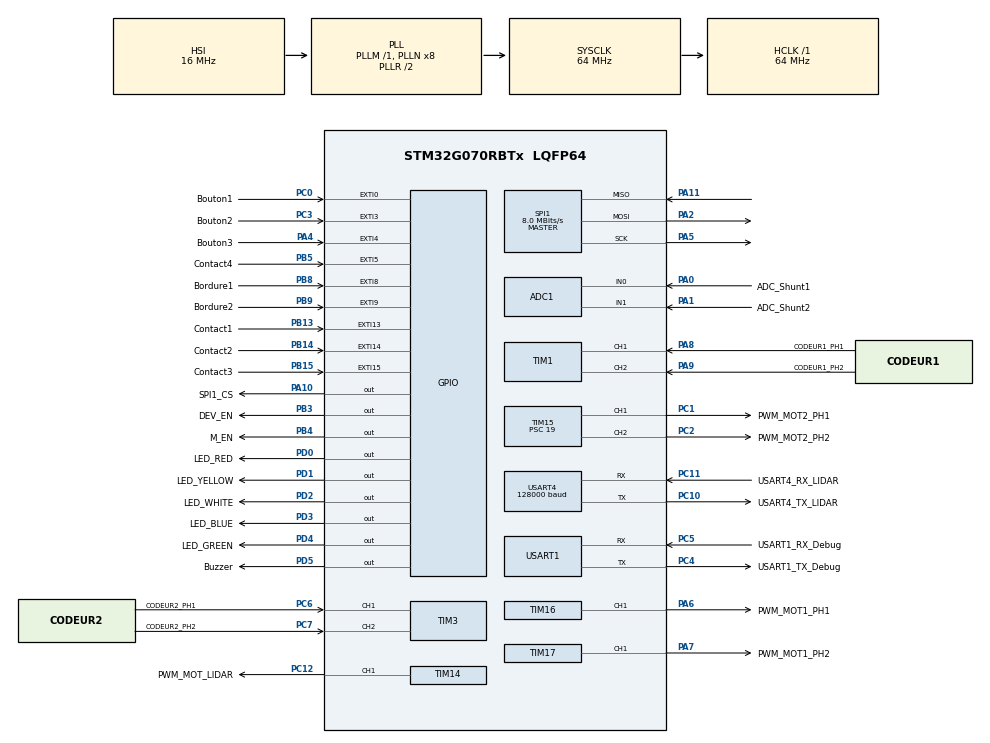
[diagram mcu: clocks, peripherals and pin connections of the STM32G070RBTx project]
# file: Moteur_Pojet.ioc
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ADC1.Channel-2\#ChannelRegularConversion=ADC_CHANNEL_0
ADC1.Channel-3\#ChannelRegularConversion=ADC_CHANNEL_1
ADC1.ContinuousConvMode=ENABLE
ADC1.DMAContinuousRequests=DISABLE
ADC1.ExternalTrigConv=ADC_SOFTWARE_START
ADC1.NbrOfConversion=2
ADC1.NbrOfConversionFlag=1
ADC1.Rank-2\#ChannelRegularConversion=1
ADC1.Rank-3\#ChannelRegularConversion=2
ADC1.SamplingTime-2\#ChannelRegularConversion=ADC_SAMPLINGTIME_COMMON_1
ADC1.SamplingTime-3\#ChannelRegularConversion=ADC_SAMPLINGTIME_COMMON_1
ADC1.SamplingTimeCommon1=ADC_SAMPLETIME_79CYCLES_5
ADC1.SamplingTimeCommon2=ADC_SAMPLETIME_79CYCLES_5
ADC1.SelectedChannel=ADC_CHANNEL_0|ADC_CHANNEL_1
ADC1.Sequencer=FULLY_CONFIGURABLE
ADC1.master=1
Dma.ADC1.0.Direction=DMA_PERIPH_TO_MEMORY
Dma.ADC1.0.EventEnable=DISABLE
Dma.ADC1.0.Instance=DMA1_Channel1
Dma.ADC1.0.MemDataAlignment=DMA_MDATAALIGN_HALFWORD
Dma.ADC1.0.MemInc=DMA_MINC_ENABLE
Dma.ADC1.0.Mode=DMA_NORMAL
Dma.ADC1.0.PeriphDataAlignment=DMA_PDATAALIGN_HALFWORD
Dma.ADC1.0.PeriphInc=DMA_PINC_DISABLE
Dma.ADC1.0.Polarity=HAL_DMAMUX_REQ_GEN_RISING
Dma.ADC1.0.Priority=DMA_PRIORITY_LOW
Dma.ADC1.0.RequestNumber=1
Dma.ADC1.0.SignalID=NONE
Dma.ADC1.0.SyncEnable=DISABLE
Dma.ADC1.0.SyncPolarity=HAL_DMAMUX_SYNC_NO_EVENT
Dma.ADC1.0.SyncRequestNumber=1
Dma.ADC1.0.SyncSignalID=NONE
Dma.Request0=ADC1
Mcu.Family=STM32G0
Mcu.Name=STM32G070RBTx
Mcu.Package=LQFP64
NVIC.DMA1_Channel1_IRQn=true\:0\:0\:false\:false\:true\:false\:true\:true
NVIC.EXTI0_1_IRQn=true\:0\:0\:false\:false\:true\:true\:true\:true
NVIC.EXTI2_3_IRQn=true\:0\:0\:false\:false\:true\:true\:true\:true
NVIC.EXTI4_15_IRQn=true\:0\:0\:false\:false\:true\:true\:true\:true
NVIC.TIM1_CC_IRQn=true\:0\:0\:false\:false\:true\:true\:true\:true
NVIC.TIM3_IRQn=true\:0\:0\:false\:false\:true\:true\:true\:true
PA0.GPIO_Label=ADC_Shunt1
PA0.Mode=IN0
PA0.Signal=ADC1_IN0
PA1.GPIO_Label=ADC_Shunt2
PA1.Mode=IN1
PA1.Signal=ADC1_IN1
PA10.GPIO_Label=SPI1_CS
PA10.PinState=GPIO_PIN_SET
PA10.Signal=GPIO_Output
PA11\ [PA9].Mode=Full_Duplex_Master
PA11\ [PA9].Signal=SPI1_MISO
PA13.Mode=Serial_Wire
PA13.Signal=SYS_SWDIO
PA14-BOOT0.Mode=Serial_Wire
PA14-BOOT0.Signal=SYS_SWCLK
PA2.Mode=Full_Duplex_Master
PA2.Signal=SPI1_MOSI
PA4.GPIO_Label=Bouton3
PA4.GPIO_PuPd=GPIO_NOPULL
PA4.Signal=GPXTI4
PA5.Mode=Full_Duplex_Master
PA5.Signal=SPI1_SCK
PA6.GPIO_Label=PWM_MOT1_PH1
PA6.Signal=S_TIM16_CH1
PA7.GPIO_Label=PWM_MOT1_PH2
PA7.Signal=S_TIM17_CH1
PA8.GPIO_Label=CODEUR1_PH1
PA8.Signal=S_TIM1_CH1
PA9.GPIO_Label=CODEUR1_PH2
PA9.Signal=S_TIM1_CH2
PB13.GPIO_Label=Contact1
PB13.GPIO_PuPd=GPIO_PULLDOWN
PB13.Signal=GPXTI13
PB14.GPIO_Label=Contact2
PB14.GPIO_PuPd=GPIO_PULLDOWN
PB14.Signal=GPXTI14
PB15.GPIO_Label=Contact3
PB15.GPIO_PuPd=GPIO_PULLDOWN
PB15.Signal=GPXTI15
PB3.GPIO_Label=DEV_EN
PB3.Signal=GPIO_Output
PB4.GPIO_Label=M_EN
PB4.Signal=GPIO_Output
PB5.GPIO_Label=Contact4
PB5.GPIO_PuPd=GPIO_PULLDOWN
PB5.Signal=GPXTI5
PB8.GPIO_Label=Bordure1
PB8.Signal=GPXTI8
PB9.GPIO_Label=Bordure2
PB9.Signal=GPXTI9
PC0.GPIO_Label=Bouton1
PC0.Signal=GPXTI0
PC1.GPIO_Label=PWM_MOT2_PH1
PC1.Signal=S_TIM15_CH1
PC10.GPIO_Label=USART4_TX_LIDAR
PC10.Mode=Asynchronous
PC10.Signal=USART4_TX
PC11.GPIO_Label=USART4_RX_LIDAR
PC11.Mode=Asynchronous
PC11.Signal=USART4_RX
PC12.GPIO_Label=PWM_MOT_LIDAR
PC12.Signal=S_TIM14_CH1
PC2.GPIO_Label=PWM_MOT2_PH2
PC2.Signal=S_TIM15_CH2
PC3.GPIO_Label=Bouton2
PC3.Signal=GPXTI3
PC4.GPIO_Label=USART1_TX_Debug
PC4.Mode=Asynchronous
PC4.Signal=USART1_TX
PC5.GPIO_Label=USART1_RX_Debug
PC5.Mode=Asynchronous
PC5.Signal=USART1_RX
PC6.GPIO_Label=CODEUR2_PH1
PC6.Signal=S_TIM3_CH1
PC7.GPIO_Label=CODEUR2_PH2
PC7.Signal=S_TIM3_CH2
PD0.GPIO_Label=LED_RED
PD0.Signal=GPIO_Output
PD1.GPIO_Label=LED_YELLOW
PD1.Signal=GPIO_Output
PD2.GPIO_Label=LED_WHITE
PD2.Signal=GPIO_Output
PD3.GPIO_Label=LED_BLUE
PD3.Signal=GPIO_Output
PD4.GPIO_Label=LED_GREEN
PD4.Signal=GPIO_Output
PD5.GPIO_Label=Buzzer
PD5.Signal=GPIO_Output
PF0-OSC_IN\ (PF0).Mode=HSE-External-Oscillator
PF0-OSC_IN\ (PF0).Signal=RCC_OSC_IN
PF1-OSC_OUT\ (PF1).Mode=HSE-External-Oscillator
PF1-OSC_OUT\ (PF1).Signal=RCC_OSC_OUT
ProjectManager.HeapSize=0x200
ProjectManager.StackSize=0x400
ProjectManager.TargetToolchain=STM32CubeIDE
RCC.ADCFreq_Value=64000000
RCC.AHBFreq_Value=64000000
RCC.CortexFreq_Value=64000000
RCC.EXTERNAL_CLOCK_VALUE=48000
RCC.HCLKFreq_Value=64000000
RCC.HSE_VALUE=16000000
RCC.HSI_VALUE=16000000
RCC.LSE_VALUE=32768
RCC.SYSCLKFreq_VALUE=64000000
RCC.SYSCLKSource=RCC_SYSCLKSOURCE_PLLCLK
RCC.VCOOutputFreq_Value=128000000
SH.S_TIM14_CH1.0=TIM14_CH1,PWM Generation1 CH1
SH.S_TIM15_CH1.0=TIM15_CH1,PWM Generation1 CH1
SH.S_TIM15_CH2.0=TIM15_CH2,PWM Generation2 CH2
SH.S_TIM16_CH1.0=TIM16_CH1,PWM Generation1 CH1
SH.S_TIM17_CH1.0=TIM17_CH1,PWM Generation1 CH1
SH.S_TIM1_CH1.0=TIM1_CH1,Encoder_Interface
SH.S_TIM1_CH2.0=TIM1_CH2,Encoder_Interface
SH.S_TIM3_CH1.0=TIM3_CH1,Encoder_Interface
SH.S_TIM3_CH2.0=TIM3_CH2,Encoder_Interface
SPI1.BaudRatePrescaler=SPI_BAUDRATEPRESCALER_8
SPI1.CLKPhase=SPI_PHASE_1EDGE
SPI1.CLKPolarity=SPI_POLARITY_LOW
SPI1.CRCCalculation=SPI_CRCCALCULATION_DISABLE
SPI1.CalculateBaudRate=8.0 MBits/s
SPI1.DataSize=SPI_DATASIZE_8BIT
SPI1.Direction=SPI_DIRECTION_2LINES
SPI1.Mode=SPI_MODE_MASTER
SPI1.NSSPMode=SPI_NSS_PULSE_DISABLE
SPI1.VirtualType=VM_MASTER
TIM1.EncoderMode=TIM_ENCODERMODE_TI12
TIM1.IC1Polarity=TIM_ICPOLARITY_FALLING
TIM1.IC2Polarity=TIM_ICPOLARITY_FALLING
TIM14.Channel=TIM_CHANNEL_1
TIM15.Channel-PWM\ Generation1\ CH1=TIM_CHANNEL_1
TIM15.Channel-PWM\ Generation2\ CH2=TIM_CHANNEL_2
TIM15.Period=999
TIM15.Prescaler=19
TIM16.Channel=TIM_CHANNEL_1
TIM16.Period=999
TIM16.Prescaler=19
TIM17.Channel=TIM_CHANNEL_1
TIM17.Period=999
TIM17.Prescaler=19
TIM3.EncoderMode=TIM_ENCODERMODE_TI12
TIM3.IC1Polarity=TIM_ICPOLARITY_FALLING
TIM3.IC2Polarity=TIM_ICPOLARITY_FALLING
TIM6.Period=99
TIM6.Prescaler=63999
TIM6.TIM_MasterOutputTrigger=TIM_TRGO_UPDATE
USART1.VirtualMode-Asynchronous=VM_ASYNC
USART4.BaudRate=128000
USART4.VirtualMode-Asynchronous=VM_ASYNC
VP_SYS_VS_DBSignals.Mode=DisableDeadBatterySignals
VP_TIM14_VS_ClockSourceINT.Mode=Enable_Timer
VP_TIM16_VS_ClockSourceINT.Mode=Enable_Timer
VP_TIM17_VS_ClockSourceINT.Mode=Enable_Timer
VP_TIM6_VS_ClockSourceINT.Mode=Enable_Timer
board=custom

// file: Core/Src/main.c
/* USER CODE BEGIN Header */
/**
 ******************************************************************************
 * @file           : main.c
 * @brief          : Main program body
 ******************************************************************************
 * @attention
 *
 * Copyright (c) 2023 STMicroelectronics.
 * All rights reserved.
 *
 * This software is licensed under terms that can be found in the LICENSE file
 * in the root directory of this software component.
 * If no LICENSE file comes with this software, it is provided AS-IS.
 *
 ******************************************************************************
 */
/* USER CODE END Header */
#include "main.h"
#include "adc.h"
#include "dma.h"
#include "spi.h"
#include "tim.h"
#include "usart.h"
#include "gpio.h"

/* USER CODE BEGIN Includes */
#include <stdio.h>
#include "IIM2070_h.h"
/* USER CODE END Includes */

/* USER CODE BEGIN PTD */
h_IIM2070_t h_IIM2070;
/* USER CODE END PTD */

void SystemClock_Config(void);

/* USER CODE BEGIN 0 */
int __io_putchar(int ch) {                                           //redirige la fonction printf
	HAL_UART_Transmit(&huart1, (uint8_t *)&ch, 1, HAL_MAX_DELAY);	 //vers l'uart2 ( pour la connexion serial avec l'ordinateur)//uart4 pour le rasppberry Pi zero
	return ch;
}

int SPI_transmit_receive(uint8_t *p_data_TX, uint8_t *p_data_RX, uint16_t size)
{
	if( HAL_SPI_TransmitReceive(&hspi1,p_data_TX,p_data_RX, size, HAL_MAX_DELAY) != HAL_OK)
	{
		printf("Error SPI transmit\r\n");
	}
	return 0;
}

/* USER CODE END 0 */

int main(void)
{

	/* MCU Configuration--------------------------------------------------------*/

	/* Reset of all peripherals, Initializes the Flash interface and the Systick. */
	HAL_Init();

	/* Configure the system clock */
	SystemClock_Config();

	/* Initialize all configured peripherals */
	MX_GPIO_Init();
	MX_DMA_Init();
	MX_ADC1_Init();
	MX_TIM1_Init();
	MX_TIM3_Init();
	MX_TIM14_Init();
	MX_TIM15_Init();
	MX_TIM16_Init();
	MX_TIM17_Init();
	MX_USART1_UART_Init();
	MX_USART4_UART_Init();
	MX_SPI1_Init();
	MX_TIM6_Init();
	/* USER CODE BEGIN 2 */
	h_IIM2070.SPI_drv.transmit_receive = SPI_transmit_receive; //Initialisation de la structure de la fonction de réception SPI
	//IIM2070_init(&h_IIM2070);
	HAL_Delay(20);
	/* USER CODE END 2 */

	/* Infinite loop */
	while (1)
	{
		IIM2070_Read_Gyro(&h_IIM2070);
		HAL_Delay(1000);
		//IIM2070_Read_Accel(&h_IIM2070);

	}
}

void SystemClock_Config(void)
{
	RCC_OscInitTypeDef RCC_OscInitStruct = {0};
	RCC_ClkInitTypeDef RCC_ClkInitStruct = {0};

	/** Configure the main internal regulator output voltage
	 */
	HAL_PWREx_ControlVoltageScaling(PWR_REGULATOR_VOLTAGE_SCALE1);

	/** Initializes the RCC Oscillators according to the specified parameters
	 * in the RCC_OscInitTypeDef structure.
	 */
	RCC_OscInitStruct.OscillatorType = RCC_OSCILLATORTYPE_HSI;
	RCC_OscInitStruct.HSIState = RCC_HSI_ON;
	RCC_OscInitStruct.HSIDiv = RCC_HSI_DIV1;
	RCC_OscInitStruct.HSICalibrationValue = RCC_HSICALIBRATION_DEFAULT;
	RCC_OscInitStruct.PLL.PLLState = RCC_PLL_ON;
	RCC_OscInitStruct.PLL.PLLSource = RCC_PLLSOURCE_HSI;
	RCC_OscInitStruct.PLL.PLLM = RCC_PLLM_DIV1;
	RCC_OscInitStruct.PLL.PLLN = 8;
	RCC_OscInitStruct.PLL.PLLP = RCC_PLLP_DIV2;
	RCC_OscInitStruct.PLL.PLLR = RCC_PLLR_DIV2;
	if (HAL_RCC_OscConfig(&RCC_OscInitStruct) != HAL_OK)
	{
		Error_Handler();
	}

	/** Initializes the CPU, AHB and APB buses clocks
	 */
	RCC_ClkInitStruct.ClockType = RCC_CLOCKTYPE_HCLK|RCC_CLOCKTYPE_SYSCLK
			|RCC_CLOCKTYPE_PCLK1;
	RCC_ClkInitStruct.SYSCLKSource = RCC_SYSCLKSOURCE_PLLCLK;
	RCC_ClkInitStruct.AHBCLKDivider = RCC_SYSCLK_DIV1;
	RCC_ClkInitStruct.APB1CLKDivider = RCC_HCLK_DIV1;

	if (HAL_RCC_ClockConfig(&RCC_ClkInitStruct, FLASH_LATENCY_2) != HAL_OK)
	{
		Error_Handler();
	}
}

void Error_Handler(void)
{
	__disable_irq();
	while (1)
	{
	}
}
